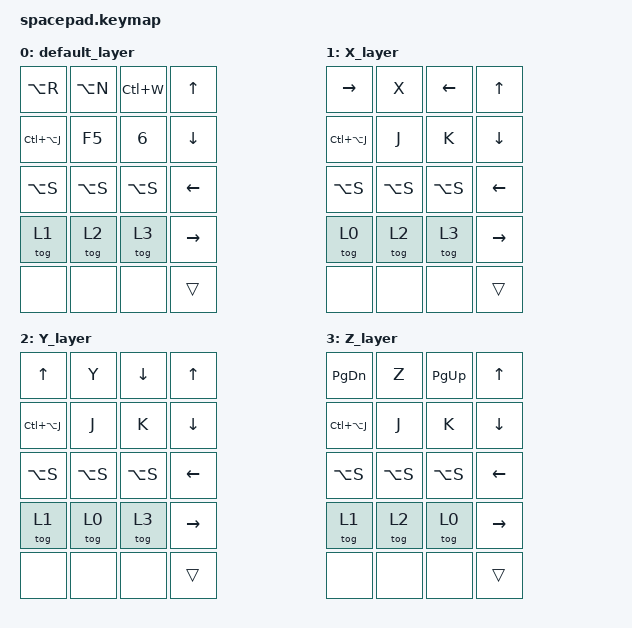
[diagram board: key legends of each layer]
/*
 * Copyright (c) 2020 The ZMK Contributors
 *
 * SPDX-License-Identifier: MIT
 */

#include <behaviors.dtsi>
#include <dt-bindings/zmk/bt.h>
#include <dt-bindings/zmk/keys.h>
#include <dt-bindings/zmk/outputs.h>

/ {
    keymap {
        compatible = "zmk,keymap";

        default_layer {
// ----------------------------------------
// | cycle start | Singleblock |  Rewind  |
// | Jog on/off  | spindle on  |  right   |
// |     Stop    |     Stop    |  Stop    |
// |   X_layer   |    Y_layer  |  Z_layer |
// ----------------------------------------
            bindings = <
    &kp LA(R)     &kp LA(N) &kp LC(W)   &kp UP_ARROW
    &kp LC(LA(J)) &kp F5    &kp N6      &kp DOWN_ARROW
    &kp LA(S)     &kp LA(S) &kp LA(S)   &kp LEFT_ARROW
    &tog 1        &tog 2    &tog 3      &kp RIGHT_ARROW
    &none         &none     &none       &trans
            >;

            sensor-bindings = <&inc_dec_kp PAGE_UP PAGE_DOWN>;
        };

         X_layer {
// --------------------------
// |       X+     |      ZeroX    |      X-     |
// |  Jog on/off  |   Jog con/inc |   stepsize  |
// |      Stop    |     Stop      |     Stop    |
// |    Default   |    Y_layer    |   Z_layer   |
// --------------------------
             bindings = <
    &kp RIGHT_ARROW     &kp X    &kp LEFT_ARROW   &kp UP_ARROW
    &kp LC(LA(J))       &kp J    &kp K            &kp DOWN_ARROW
    &kp LA(S)           &kp LA(S)&kp LA(S)        &kp LEFT_ARROW
    &tog 0              &tog 2   &tog 3           &kp RIGHT_ARROW
    &none               &none    &none            &trans
             >;

             sensor-bindings = <&inc_dec_kp LEFT_ARROW RIGHT_ARROW>;
         };
        
         Y_layer {
// --------------------------
// |       Y+     |      ZeroY    |      Y-     |
// |  Jog on/off  |   Jog con/inc |   stepsize  |
// |      Stop    |     Stop      |     Stop    |
// |    X_layer   |    Default    |   Z_layer   |
// --------------------------
             bindings = <
    &kp UP_ARROW        &kp Y    &kp DOWN_ARROW   &kp UP_ARROW
    &kp LC(LA(J))       &kp J    &kp K            &kp DOWN_ARROW
    &kp LA(S)           &kp LA(S)&kp LA(S)        &kp LEFT_ARROW
    &tog 1              &tog 0   &tog 3           &kp RIGHT_ARROW
    &none               &none    &none            &trans
             >;

             sensor-bindings = <&inc_dec_kp DOWN_ARROW UP_ARROW>;
         };
         
         Z_layer {
// --------------------------
// |       Z+     |      ZeroZ    |      Z-     |
// |  Jog on/off  |   Jog con/inc |   stepsize  |
// |      Stop    |     Stop      |     Stop    |
// |    X_layer   |    Y_layer    |   Default   |
// --------------------------
             bindings = <
    &kp PAGE_DOWN       &kp Z    &kp PAGE_UP      &kp UP_ARROW
    &kp LC(LA(J))       &kp J    &kp K            &kp DOWN_ARROW
    &kp LA(S)           &kp LA(S)&kp LA(S)        &kp LEFT_ARROW
    &tog 1              &tog 2   &tog 0           &kp RIGHT_ARROW
    &none               &none    &none            &trans
             >;

             sensor-bindings = <&inc_dec_kp PAGE_UP PAGE_DOWN>;
         };
    };
};
